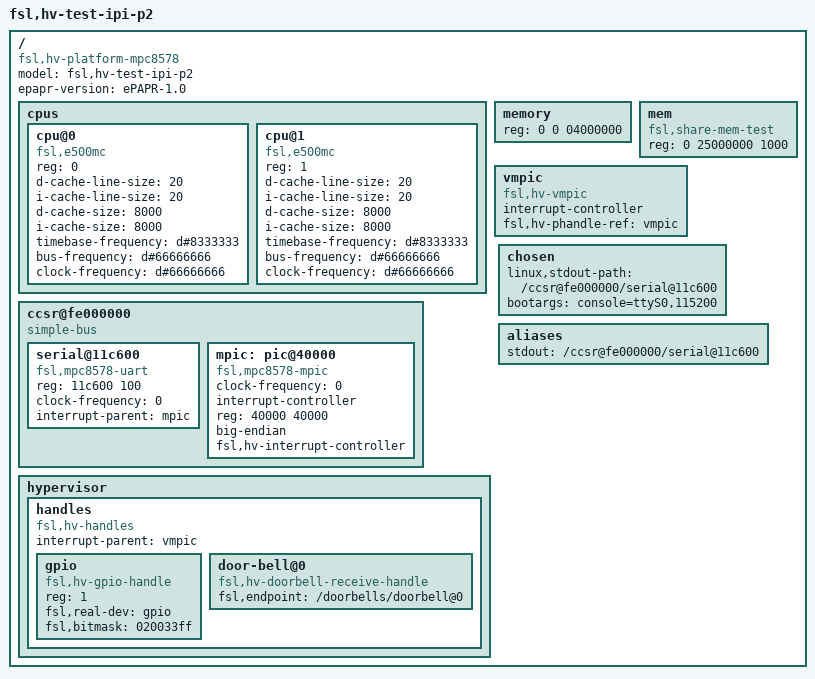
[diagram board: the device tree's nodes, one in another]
/ {
	compatible = "fsl,hv-platform-mpc8578",
                     "fsl,hv-platform";
	model = "fsl,hv-test-ipi-p2";
	epapr-version = "ePAPR-1.0";
	#address-cells = <2>;
	#size-cells = <1>;

	cpus {
		#address-cells = <1>;
		#size-cells = <0>;

		cpu@0 {
			device_type = "cpu";
			compatible = "fsl,e500mc", "fsl,e500";
			reg = <0>;
			d-cache-line-size = <20>;
			i-cache-line-size = <20>;
			d-cache-size = <8000>;
			i-cache-size = <8000>;
			timebase-frequency = <d#8333333>;
			bus-frequency = <d#66666666>;
			clock-frequency = <d#66666666>;
		};

		cpu@1 {
			device_type = "cpu";
			compatible = "fsl,e500mc", "fsl,e500";
			reg = <1>;
			d-cache-line-size = <20>;
			i-cache-line-size = <20>;
			d-cache-size = <8000>;
			i-cache-size = <8000>;
			timebase-frequency = <d#8333333>;
			bus-frequency = <d#66666666>;
			clock-frequency = <d#66666666>;
		};

	};

	memory {
		reg = <0 0 04000000>;
		device_type = "memory";
	};

	mem {
		reg = <0 25000000 1000>;
		compatible = "fsl,share-mem-test";
	};

	ccsr@fe000000 {
		#address-cells = <1>;
		#size-cells = <1>;
		compatible = "simple-bus";
		device_type = "soc";
		ranges = <0 0 fe000000 400000>;

		serial@11c600 {
			device_type = "serial";
			compatible = "fsl,mpc8578-uart",
			             "fsl,ns16550", "ns16550";
			reg = <11c600 100>;
			clock-frequency = <0>;
//			interrupts = <1c 2>;
			interrupt-parent = <&mpic>;
		};

		mpic: pic@40000 {
			clock-frequency = <0>;
			interrupt-controller;
			#address-cells = <0>;
			#interrupt-cells = <2>;
			reg = <40000 40000>;
			compatible = "fsl,mpc8578-mpic", "fsl,mpic",
			             "chrp,open-pic";
			device_type = "open-pic";
			big-endian;
			fsl,hv-interrupt-controller;
		};
	};

	vmpic:vmpic {
		compatible = "fsl,hv-vmpic";
		interrupt-controller;
		#interrupt-cells = <2>;
		fsl,hv-phandle-ref = <&vmpic>;
	};

	hypervisor {
		handles {
			#address-cells = <1>;
			#size-cells = <0>;
			compatible = "fsl,hv-handles";
			interrupt-parent = <&vmpic>;
	
			gpio {
				reg = <1>;
				compatible = "fsl,hv-gpio-handle";
				fsl,real-dev = "gpio";
				fsl,bitmask = <020033ff>;
			};
	
			door-bell@0 {
				compatible = "fsl,hv-doorbell-receive-handle";
				fsl,endpoint = "/doorbells/doorbell@0";
			};
		};
	};

	chosen {
		linux,stdout-path = "/ccsr@fe000000/serial@11c600";
		bootargs = "console=ttyS0,115200";
	};

	aliases {
		stdout = "/ccsr@fe000000/serial@11c600";
	};
};
